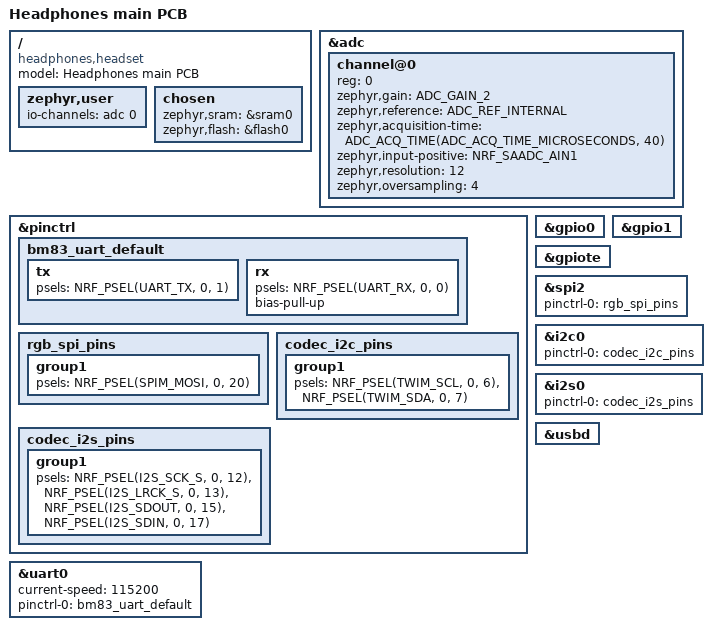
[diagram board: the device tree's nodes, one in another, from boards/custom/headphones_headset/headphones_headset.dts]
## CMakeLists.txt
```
cmake_minimum_required(VERSION 3.20.0)
list(APPEND BOARD_ROOT "${CMAKE_CURRENT_SOURCE_DIR}")
list(APPEND EXTRA_CONF_FILE "${CMAKE_CURRENT_SOURCE_DIR}/../common/radio.conf")
find_package(Zephyr REQUIRED HINTS $ENV{ZEPHYR_BASE})
project(headphone_headset)
target_sources(app PRIVATE
    src/main.c
    src/headset_logic.c
    src/battery.c
    src/bm83_link.c
    src/bm83_protocol.c
    src/codec.c
    src/rgb.c
    src/wireless_audio.c
    ../common/audio.c
    ../common/audio_fifo.c
    ../common/radio.c
    ../common/rgb_frame.c
)
target_include_directories(app PRIVATE ../common)
```

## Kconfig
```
mainmenu "Headphones"

config HEADSET_USB_VID
    hex "Assigned headset USB vendor ID"
    range 0x0000 0xffff
    default 0

config HEADSET_USB_PID
    hex "Assigned headset USB product ID"
    range 0x0000 0xffff
    default 0

source "Kconfig.zephyr"
```

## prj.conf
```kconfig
CONFIG_GPIO=y
CONFIG_ADC=y
CONFIG_PRINTK=y
CONFIG_CONSOLE=y
CONFIG_SERIAL=y
CONFIG_UART_INTERRUPT_DRIVEN=y
CONFIG_UART_CONSOLE=n
CONFIG_CLOCK_CONTROL_NRF_K32SRC_RC=y
CONFIG_USE_SEGGER_RTT=y
CONFIG_RTT_CONSOLE=y
CONFIG_SPI=y
CONFIG_I2C=y
CONFIG_USB_DEVICE_STACK_NEXT=y
CONFIG_USBD_HID_SUPPORT=y
CONFIG_BT_PERIPHERAL=y
CONFIG_BT_FILTER_ACCEPT_LIST=y
CONFIG_I2S=y
```

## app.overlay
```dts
#include "../common/flash.dtsi"

/ {
    headphone_rgb: headphone_rgb {
        compatible = "zephyr,hid-device";
        label = "Headphone RGB";
        in-report-size = <64>;
        in-polling-period-us = <4000>;
    };
};
```

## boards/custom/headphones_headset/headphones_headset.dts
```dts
/dts-v1/;

#include <nordic/nrf52840_qiaa.dtsi>
#include <zephyr/dt-bindings/adc/adc.h>
#include <zephyr/dt-bindings/adc/nrf-saadc.h>
#include <zephyr/dt-bindings/pinctrl/nrf-pinctrl.h>

/ {
    model = "Headphones main PCB";
    compatible = "headphones,headset";

    zephyr,user {
        io-channels = <&adc 0>;
    };

    chosen {
        zephyr,sram = &sram0;
        zephyr,flash = &flash0;
    };
};

&adc {
    status = "okay";
    #address-cells = <1>;
    #size-cells = <0>;

    channel@0 {
        reg = <0>;
        zephyr,gain = "ADC_GAIN_2";
        zephyr,reference = "ADC_REF_INTERNAL";
        zephyr,acquisition-time = <ADC_ACQ_TIME(ADC_ACQ_TIME_MICROSECONDS, 40)>;
        zephyr,input-positive = <NRF_SAADC_AIN1>;
        zephyr,resolution = <12>;
        zephyr,oversampling = <4>;
    };
};

&pinctrl {
    bm83_uart_default: bm83_uart_default {
        tx {
            psels = <NRF_PSEL(UART_TX, 0, 1)>;
        };
        rx {
            psels = <NRF_PSEL(UART_RX, 0, 0)>;
            bias-pull-up;
        };
    };
    rgb_spi_pins: rgb_spi_pins {
        group1 {
            psels = <NRF_PSEL(SPIM_MOSI, 0, 20)>;
        };
    };
    codec_i2c_pins: codec_i2c_pins {
        group1 {
            psels = <NRF_PSEL(TWIM_SCL, 0, 6)>,
                    <NRF_PSEL(TWIM_SDA, 0, 7)>;
        };
    };
    codec_i2s_pins: codec_i2s_pins {
        group1 {
            psels = <NRF_PSEL(I2S_SCK_S, 0, 12)>,
                    <NRF_PSEL(I2S_LRCK_S, 0, 13)>,
                    <NRF_PSEL(I2S_SDOUT, 0, 15)>,
                    <NRF_PSEL(I2S_SDIN, 0, 17)>;
        };
    };
};

&gpio0 {
    status = "okay";
};

&gpio1 {
    status = "okay";
};

&gpiote {
    status = "okay";
};

&uart0 {
    status = "okay";
    current-speed = <115200>;
    pinctrl-0 = <&bm83_uart_default>;
    pinctrl-names = "default";
};

&spi2 {
    status = "okay";
    pinctrl-0 = <&rgb_spi_pins>;
    pinctrl-names = "default";
};

&i2c0 {
    status = "okay";
    pinctrl-0 = <&codec_i2c_pins>;
    pinctrl-names = "default";
};

&i2s0 {
    status = "okay";
    pinctrl-0 = <&codec_i2s_pins>;
    pinctrl-names = "default";
};

zephyr_udc0: &usbd {
    status = "okay";
};
```

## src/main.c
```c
#include <stdbool.h>
#include <stdint.h>

#include <zephyr/device.h>
#include <zephyr/drivers/gpio.h>
#include <zephyr/kernel.h>
#include <zephyr/sys/printk.h>

#include "bm83_link.h"
#include "audio_control.h"
#include "battery.h"
#include "codec.h"
#include "headset_logic.h"
#include "rgb.h"
#include "wireless_audio.h"

enum {
    PIN_MODE_N = 29,
    PIN_PAIR_N = 4,
    PIN_PLAY_N = 24,
    PIN_DOWN_N = 0,
    PIN_UP_N = 2,
    PIN_RGB_ENABLE = 22,
    PIN_BT_AUDIO_SEL = 31,
    PIN_CHG_N = 4,
    PIN_PGOOD_N = 5,
    PIN_BOOM_N = 11,
};

static const struct device *const gpio0 = DEVICE_DT_GET(DT_NODELABEL(gpio0));
static const struct device *const gpio1 = DEVICE_DT_GET(DT_NODELABEL(gpio1));

int main(void)
{
    struct headset_inputs inputs = {0};
    struct headset_input boom = {0};
    bool bluetooth_routed = false;
    int last_charger_status = -1;

    if (!device_is_ready(gpio0) || !device_is_ready(gpio1)) {
        printk("GPIO unavailable\n");
        return 1;
    }

    if (gpio_pin_configure(gpio0, PIN_RGB_ENABLE, GPIO_OUTPUT_INACTIVE) < 0 ||
        gpio_pin_configure(gpio0, PIN_BT_AUDIO_SEL, GPIO_OUTPUT_INACTIVE) < 0 ||
        gpio_pin_configure(gpio0, PIN_CHG_N, GPIO_INPUT) < 0 ||
        gpio_pin_configure(gpio0, PIN_PGOOD_N, GPIO_INPUT) < 0 ||
        gpio_pin_configure(gpio0, PIN_MODE_N, GPIO_INPUT) < 0 ||
        gpio_pin_configure(gpio1, PIN_BOOM_N, GPIO_INPUT | GPIO_PULL_UP) < 0 ||
        gpio_pin_configure(gpio1, PIN_PAIR_N, GPIO_INPUT | GPIO_PULL_UP) < 0 ||
        gpio_pin_configure(gpio0, PIN_PLAY_N, GPIO_INPUT | GPIO_PULL_UP) < 0 ||
        gpio_pin_configure(gpio1, PIN_DOWN_N, GPIO_INPUT | GPIO_PULL_UP) < 0 ||
        gpio_pin_configure(gpio1, PIN_UP_N, GPIO_INPUT | GPIO_PULL_UP) < 0) {
        printk("GPIO setup failed\n");
        return 1;
    }

    printk("Headset bring-up\n");
    const int battery_status = battery_start();
    if (battery_status < 0) {
        printk("Battery monitor unavailable: %d\n", battery_status);
    }
    const int codec_status = codec_prepare();
    printk("Codec clock register setup: %d\n", codec_status);
    const int bt_status = bm83_start();
    if (bt_status < 0) {
        printk("BM83 UART setup failed: %d\n", bt_status);
    }
    if (codec_status == 0) {
        const int wireless_status = wireless_audio_start();
        if (wireless_status < 0) {
            printk("Dongle audio setup failed: %d\n", wireless_status);
        }
    }
    const int rgb_status = rgb_start();
    if (rgb_status < 0) {
        printk("RGB over USB unavailable: %d\n", rgb_status);
    }

    for (;;) {
        const int mode = gpio_pin_get_raw(gpio0, PIN_MODE_N);
        const int pair = gpio_pin_get_raw(gpio1, PIN_PAIR_N);
        const int play = gpio_pin_get_raw(gpio0, PIN_PLAY_N);
        const int down = gpio_pin_get_raw(gpio1, PIN_DOWN_N);
        const int up = gpio_pin_get_raw(gpio1, PIN_UP_N);
        const int pgood = gpio_pin_get_raw(gpio0, PIN_PGOOD_N);
        const int charging = gpio_pin_get_raw(gpio0, PIN_CHG_N);

        if (mode < 0 || pair < 0 || play < 0 || down < 0 || up < 0) {
            printk("Input read failed\n");
            return 1;
        }

        const uint32_t now = k_uptime_get_32();
        const bool boom_muted = !headset_boom_deployed(&boom,
            gpio_pin_get_raw(gpio1, PIN_BOOM_N) == 0, now);
        bm83_set_mic_muted(boom_muted);
        wireless_audio_set_mic_muted(boom_muted);
        if (battery_status == 0) {
            battery_poll(now);
        }
        const uint8_t events = headset_inputs_update(&inputs, mode == 0, pair == 0, now);
        const bool play_pressed = headset_button_pressed(&inputs.play, play == 0, now);
        const bool down_pressed = headset_button_pressed(&inputs.volume_down, down == 0, now);
        const bool up_pressed = headset_button_pressed(&inputs.volume_up, up == 0, now);
        if (pgood >= 0 && charging >= 0) {
            const int charger_status = pgood != 0 ? 0 : (charging == 0 ? 2 : 1);
            if (charger_status != last_charger_status) {
                const char *const statuses[] = {"No valid input", "Input valid", "Charging"};
                printk("Charger: %s\n", statuses[charger_status]);
                last_charger_status = charger_status;
            }
        }

        if ((events & HEADSET_MODE_CHANGED) != 0U) {
            printk("Requested source: %s\n", inputs.mode_bluetooth.stable ?
                   "Bluetooth" : "USB dongle");
            if (bt_status == 0) {
                bm83_set_selected(inputs.mode_bluetooth.stable);
            }
            wireless_audio_select(!inputs.mode_bluetooth.stable);
        }
        if (!inputs.mode_bluetooth.stable) {
            if ((events & HEADSET_PAIR_PRESSED) != 0U) {
                wireless_audio_pair();
            }
            if (play_pressed) {
                wireless_audio_media(AUDIO_PLAY_PAUSE);
            }
            if (down_pressed) {
                wireless_audio_media(AUDIO_VOLUME_DOWN);
            }
            if (up_pressed) {
                wireless_audio_media(AUDIO_VOLUME_UP);
            }
        }
        if (bt_status == 0) {
            if ((events & HEADSET_PAIR_PRESSED) != 0U) {
                bm83_request_pairing();
            }
            if (play_pressed) {
                bm83_request_media(BM83_MEDIA_PLAY_PAUSE);
            }
            if (down_pressed) {
                bm83_request_media(BM83_MEDIA_VOLUME_DOWN);
            }
            if (up_pressed) {
                bm83_request_media(BM83_MEDIA_VOLUME_UP);
            }
            bm83_poll();
            const bool route_bluetooth = bm83_audio_available();
            if (route_bluetooth != bluetooth_routed) {
                if (gpio_pin_set(gpio0, PIN_BT_AUDIO_SEL, route_bluetooth) < 0) {
                    printk("Audio switch update failed\n");
                    return 1;
                }
                bluetooth_routed = route_bluetooth;
            }
        }

        rgb_poll(pgood <= 0);
        wireless_audio_poll();
        k_msleep(5);
    }
}
```

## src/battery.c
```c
#include "battery.h"

#include <errno.h>
#include <stdbool.h>
#include <zephyr/drivers/adc.h>
#include <zephyr/sys/printk.h>

enum {
    SAMPLE_PERIOD_MS = 30000,
    PACK_DIVIDER_UPPER_KOHMS = 1000,
    PACK_DIVIDER_LOWER_KOHMS = 56,
};

static const struct adc_dt_spec pack_adc = ADC_DT_SPEC_GET(DT_PATH(zephyr_user));
static uint32_t last_sample;
static bool sampled;

int battery_start(void)
{
    return adc_is_ready_dt(&pack_adc) ? adc_channel_setup_dt(&pack_adc) : -ENODEV;
}

void battery_poll(uint32_t now)
{
    if (sampled && now - last_sample < SAMPLE_PERIOD_MS) {
        return;
    }
    sampled = true;
    last_sample = now;

    int16_t sample;
    struct adc_sequence sequence = {.buffer = &sample, .buffer_size = sizeof(sample)};
    int status = adc_sequence_init_dt(&pack_adc, &sequence);
    if (status == 0) {
        status = adc_read_dt(&pack_adc, &sequence);
    }
    if (status < 0) {
        printk("Battery ADC error: %d\n", status);
        return;
    }
    if (sample <= 0) {
        printk("Battery: pack voltage unavailable\n");
        return;
    }

    int32_t sense_uv = sample;
    status = adc_raw_to_microvolts_dt(&pack_adc, &sense_uv);
    if (status < 0) {
        printk("Battery conversion error: %d\n", status);
        return;
    }
    const int32_t pack_mv = sense_uv * (PACK_DIVIDER_UPPER_KOHMS + PACK_DIVIDER_LOWER_KOHMS) /
                            (1000 * PACK_DIVIDER_LOWER_KOHMS);
    printk("Battery: %d mV\n", (int)pack_mv);
}
```

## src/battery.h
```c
#ifndef HEADPHONES_BATTERY_H
#define HEADPHONES_BATTERY_H

#include <stdint.h>

int battery_start(void);
void battery_poll(uint32_t now);

#endif
```

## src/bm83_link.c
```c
#include "bm83_link.h"
#include "bm83_protocol.h"

#include <errno.h>
#include <stdint.h>
#include <zephyr/device.h>
#include <zephyr/drivers/gpio.h>
#include <zephyr/drivers/uart.h>
#include <zephyr/kernel.h>
#include <zephyr/sys/atomic.h>
#include <zephyr/sys/printk.h>
#include <zephyr/sys/ring_buffer.h>

enum {
    PIN_MFB = 6,
    ACK_MS = 200,
    RESPONSE_MS = 800,
    POWER_ON_MS = 2000,
    PAIR_MS = 30000,
    RX_GAP_MS = 30,
    MAX_ATTEMPTS = 3,
};

static const struct device *const serial = DEVICE_DT_GET(DT_NODELABEL(uart0));
static const struct device *const mfb_gpio = DEVICE_DT_GET(DT_NODELABEL(gpio1));
RING_BUF_DECLARE(received, 1024);
K_MSGQ_DEFINE(media_queue, sizeof(enum bm83_media_control), 8, 1);
static atomic_t rx_overflow;
static struct bm83_parser parser;
static uint32_t last_rx;
static uint32_t sent_at;
static uint32_t pair_started;
static uint32_t power_started;
static uint8_t awaiting;
static uint8_t action;
static uint8_t command_link;
static uint8_t attempts;
static uint8_t handsfree_links;
static uint8_t hf_device[2];
static uint8_t media_links;
static uint8_t call_link = UINT8_MAX;
static bool command_pending;
static bool command_acknowledged;
static bool selected;
static bool probe_needed;
static bool responsive;
static bool pair_requested;
static bool pairing;
static bool exit_pairing;
static bool power_release_needed;
static bool power_requested;
static bool power_starting;
static bool powered;
static bool mic_muted = true;
static bool mic_update_pending;

static void command_failed(void)
{
    command_pending = false;
    if (awaiting == BM83_CMD_VERSION ||
        (awaiting == BM83_CMD_MMI &&
         (action == BM83_ACTION_POWER_PRESS || action == BM83_ACTION_POWER_RELEASE))) {
        pair_requested = false;
        power_requested = false;
    }
}

static void receive_irq(const struct device *dev, void *context)
{
    uint8_t bytes[32];
    (void)context;

    if (!uart_irq_update(dev) || !uart_irq_rx_ready(dev)) {
        return;
    }
    int count;
    while ((count = uart_fifo_read(dev, bytes, sizeof(bytes))) > 0) {
        if (ring_buf_put(&received, bytes, (uint32_t)count) != (uint32_t)count) {
            atomic_set(&rx_overflow, 1);
        }
    }
}

static int send_frame(uint8_t command, const uint8_t *params, size_t count)
{
    uint8_t frame[12];
    const size_t length = bm83_encode(frame, sizeof(frame), command, params, count);
    if (length == 0U) {
        return -EINVAL;
    }
    int status = gpio_pin_set(mfb_gpio, PIN_MFB, 1);
    if (status < 0) {
        return status;
    }
    k_busy_wait(2500);
    for (size_t i = 0; i < length; ++i) {
        uart_poll_out(serial, frame[i]);
    }
    k_busy_wait(100);
    return gpio_pin_set(mfb_gpio, PIN_MFB, 0);
}

static void send_pending(void)
{
    uint8_t params[6] = {command_link, action};
    size_t count = awaiting == BM83_CMD_VERSION ? 1U : 2U;
    if (awaiting == BM83_CMD_SET_GAIN) {
        params[0] = call_link < 2U ? call_link : (media_links & 1U ? 0U : 1U);
        params[1] = call_link < 2U ? 0x02 : 0x01;
        params[2] = action;
        count = sizeof(params);
    }
    const int status = send_frame(awaiting, params, count);
    sent_at = k_uptime_get_32();
    ++attempts;
    command_pending = status == 0;
    command_acknowledged = false;
    if (status < 0) {
        command_failed();
        printk("BM83 transmit GPIO error: %d\n", status);
    }
}

static void queue_command(uint8_t command, uint8_t mmi_action, uint8_t link)
{
    awaiting = command;
    action = mmi_action;
    command_link = link;
    attempts = 0;
    send_pending();
}

static void handle_event(uint32_t now)
{
    const uint8_t event = parser.body[0];

    if (event == BM83_EVENT_COMMAND_ACK) {
        if (parser.length < 3U || !command_pending || parser.body[1] != awaiting) {
            return;
        }
        if (parser.body[2] != 0U) {
            printk("BM83 rejected 0x%02x: 0x%02x\n", awaiting, parser.body[2]);
            command_failed();
        } else if (awaiting == BM83_CMD_MMI) {
            command_pending = false;
            switch (action) {
            case BM83_ACTION_POWER_PRESS:
                power_release_needed = true;
                break;
            case BM83_ACTION_POWER_RELEASE:
                power_starting = !powered;
                power_started = now;
                printk("BM83 accepted power-on sequence\n");
                break;
            case BM83_ACTION_MIC_MUTE:
            case BM83_ACTION_MIC_UNMUTE:
                break;
            default:
                pairing = action == BM83_ACTION_PAIR;
                pair_started = now;
                exit_pairing = pairing && !selected;
                printk("BM83 accepted pairing %s\n", pairing ? "start" : "exit");
                break;
            }
        } else if (awaiting == BM83_CMD_VERSION) {
            command_acknowledged = true;
            sent_at = now;
        } else {
            command_pending = false;
        }
        return;
    }

    if (send_frame(BM83_CMD_EVENT_ACK, &event, 1) < 0) {
        printk("BM83 event acknowledgement failed\n");
    }
    if (event == BM83_EVENT_VERSION && parser.length >= 4U && parser.body[1] == 0U) {
        responsive = true;
        if (command_pending && awaiting == BM83_CMD_VERSION) {
            command_pending = false;
        }
        printk("BM83 UART version reply received\n");
    } else if (event == BM83_EVENT_STATUS && parser.length >= 2U) {
        const uint8_t link = parser.length >= 3U ? parser.body[2] & 0x0fU : UINT8_MAX;
        const uint8_t mask = link < 2U ? 1U << link : 0U;
        printk("BM83 status 0x%02x\n", parser.body[1]);
        switch (parser.body[1]) {
        case 0x00:
            powered = false;
            pairing = false;
            handsfree_links = 0U;
            media_links = 0U;
            call_link = UINT8_MAX;
            break;
        case 0x01:
            powered = true;
            if (!pairing) {
                pair_started = now;
            }
            pairing = true;
            exit_pairing |= !selected;
            break;
        case 0x02:
            powered = true;
            break;
        case 0x03:
        case 0x04:
            pairing = false;
            exit_pairing = false;
            break;
        case 0x05:
            handsfree_links |= mask;
            if (mask != 0U) {
                hf_device[link] = parser.body[2] >> 4;
            }
            powered = true;
            break;
        case 0x06:
            media_links |= mask;
            powered = true;
            break;
        case 0x07:
            handsfree_links &= ~mask;
            if (call_link == link) {
                call_link = UINT8_MAX;
            }
            break;
        case 0x08:
            media_links &= ~mask;
            break;
        case 0x09:
            call_link = UINT8_MAX;
            for (uint8_t index = 0; index < 2U; ++index) {
                if ((handsfree_links & (1U << index)) != 0U && hf_device[index] == link) {
                    call_link = index;
                    mic_update_pending = true;
                    break;
                }
            }
            break;
        case 0x0a:
            call_link = UINT8_MAX;
            break;
        default:
            break;
        }
    }
}

int bm83_start(void)
{
    if (!device_is_ready(serial) || !device_is_ready(mfb_gpio)) {
        return -ENODEV;
    }
    int status = gpio_pin_configure(mfb_gpio, PIN_MFB, GPIO_OUTPUT_INACTIVE);
    if (status < 0) {
        return status;
    }
    status = uart_irq_callback_user_data_set(serial, receive_irq, NULL);
    if (status < 0) {
        return status;
    }
    uart_irq_rx_enable(serial);
    return 0;
}

void bm83_set_selected(bool enabled)
{
    mic_update_pending |= selected != enabled;
    selected = enabled;
    if (enabled && !responsive && !command_pending) {
        probe_needed = true;
    }
    power_requested = enabled && !powered;
    if (!enabled) {
        pair_requested = false;
        exit_pairing |= pairing;
        k_msgq_purge(&media_queue);
    }
}

void bm83_set_mic_muted(bool muted)
{
    mic_update_pending |= mic_muted != muted;
    mic_muted = muted;
}

void bm83_request_media(enum bm83_media_control control)
{
    if (selected && powered) {
        (void)k_msgq_put(&media_queue, &control, K_NO_WAIT);
    }
}

void bm83_request_pairing(void)
{
    if (selected) {
        pair_requested = true;
        power_requested |= !powered;
        probe_needed |= !responsive && !command_pending;
    }
}

bool bm83_audio_available(void)
{
    return selected && powered;
}

void bm83_poll(void)
{
    uint32_t now = k_uptime_get_32();
    uint8_t byte;

    if (atomic_cas(&rx_overflow, 1, 0) || now - last_rx > RX_GAP_MS) {
        parser.count = 0;
    }
    while (ring_buf_get(&received, &byte, 1) == 1U) {
        last_rx = now;
        if (bm83_parse_byte(&parser, byte)) {
            handle_event(now);
        }
    }

    now = k_uptime_get_32();
    if (power_starting && (powered || now - power_started >= POWER_ON_MS)) {
        power_starting = false;
        if (!powered) {
            pair_requested = false;
            printk("BM83 did not report power on\n");
        }
    }
    if (command_pending) {
        const uint32_t wait = command_acknowledged ? RESPONSE_MS : ACK_MS;
        if (now - sent_at < wait) {
            return;
        }
        const bool stale_mic_command = awaiting == BM83_CMD_MMI &&
            (action == BM83_ACTION_MIC_MUTE || action == BM83_ACTION_MIC_UNMUTE) &&
            (command_link != call_link ||
             action != ((mic_muted || !selected) ? BM83_ACTION_MIC_MUTE : BM83_ACTION_MIC_UNMUTE));
        if (!stale_mic_command && attempts < MAX_ATTEMPTS &&
            (awaiting == BM83_CMD_VERSION || awaiting == BM83_CMD_MMI)) {
            send_pending();
            return;
        }
        printk("BM83 command 0x%02x timed out\n", awaiting);
        command_failed();
    }
    if (power_release_needed) {
        power_release_needed = false;
        queue_command(BM83_CMD_MMI, BM83_ACTION_POWER_RELEASE, 0);
    } else if (mic_update_pending && powered && call_link < 2U) {
        mic_update_pending = false;
        queue_command(BM83_CMD_MMI,
            (mic_muted || !selected) ? BM83_ACTION_MIC_MUTE : BM83_ACTION_MIC_UNMUTE, call_link);
    } else if (probe_needed && selected) {
        probe_needed = false;
        queue_command(BM83_CMD_VERSION, 0, 0);
    } else if (exit_pairing || (pairing && now - pair_started >= PAIR_MS)) {
        exit_pairing = false;
        pairing = false;
        queue_command(BM83_CMD_MMI, BM83_ACTION_EXIT_PAIR, 0);
    } else if (selected && responsive && power_requested && !power_starting) {
        power_requested = false;
        if (!powered) {
            queue_command(BM83_CMD_MMI, BM83_ACTION_POWER_PRESS, 0);
        }
    } else if (selected && responsive && powered && pair_requested) {
        pair_requested = false;
        queue_command(BM83_CMD_MMI, BM83_ACTION_PAIR, 0);
    } else if (selected && powered) {
        enum bm83_media_control control;
        if (k_msgq_get(&media_queue, &control, K_NO_WAIT) != 0) {
            return;
        }
        if (control == BM83_MEDIA_PLAY_PAUSE && media_links != 0U && call_link == UINT8_MAX) {
            queue_command(BM83_CMD_MUSIC_CONTROL, 0x07, 0);
        } else if (control != BM83_MEDIA_PLAY_PAUSE &&
                   (media_links != 0U || call_link < 2U)) {
            queue_command(BM83_CMD_SET_GAIN, control == BM83_MEDIA_VOLUME_UP ? 0x01 : 0x02, 0);
        }
    }
}
```

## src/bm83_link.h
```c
#ifndef BM83_LINK_H
#define BM83_LINK_H

#include <stdbool.h>

enum bm83_media_control {
    BM83_MEDIA_PLAY_PAUSE,
    BM83_MEDIA_VOLUME_DOWN,
    BM83_MEDIA_VOLUME_UP,
};

int bm83_start(void);
void bm83_poll(void);
void bm83_set_selected(bool selected);
void bm83_set_mic_muted(bool muted);
void bm83_request_pairing(void);
void bm83_request_media(enum bm83_media_control control);
bool bm83_audio_available(void);

#endif
```

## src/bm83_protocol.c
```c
#include "bm83_protocol.h"

#include <string.h>

bool bm83_parse_byte(struct bm83_parser *parser, uint8_t byte)
{
    switch (parser->count) {
    case 0:
        if (byte == BM83_START) {
            parser->count = 1;
        }
        return false;
    case 1:
        parser->length = (uint16_t)byte << 8;
        parser->checksum = byte;
        break;
    case 2:
        parser->length |= byte;
        if (parser->length == 0U || parser->length > sizeof(parser->body)) {
            parser->count = byte == BM83_START ? 1U : 0U;
            return false;
        }
        break;
    default:
        if (parser->count == parser->length + 3U) {
            const bool valid = (uint8_t)(parser->checksum + byte) == 0U;
            parser->count = !valid && byte == BM83_START ? 1U : 0U;
            return valid;
        }
        parser->body[parser->count - 3U] = byte;
        break;
    }
    if (parser->count > 1U) {
        parser->checksum = (uint8_t)(parser->checksum + byte);
    }
    ++parser->count;
    return false;
}

size_t bm83_encode(uint8_t *out, size_t capacity, uint8_t command,
                   const uint8_t *params, size_t count)
{
    if (count >= BM83_MAX_BODY || capacity < count + 5U ||
        (count != 0U && params == NULL)) {
        return 0;
    }

    const uint16_t length = (uint16_t)(count + 1U);
    out[0] = BM83_START;
    out[1] = (uint8_t)(length >> 8);
    out[2] = (uint8_t)length;
    out[3] = command;
    if (count != 0U) {
        memcpy(&out[4], params, count);
    }

    uint8_t checksum = 0;
    for (size_t i = 1; i < count + 4U; ++i) {
        checksum = (uint8_t)(checksum + out[i]);
    }
    out[4U + count] = (uint8_t)(0U - checksum);
    return count + 5U;
}
```

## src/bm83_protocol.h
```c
#ifndef BM83_PROTOCOL_H
#define BM83_PROTOCOL_H

#include <stdbool.h>
#include <stddef.h>
#include <stdint.h>

enum {
    BM83_START = 0xaa,
    BM83_MAX_BODY = 512,
    BM83_EVENT_COMMAND_ACK = 0x00,
    BM83_EVENT_STATUS = 0x01,
    BM83_EVENT_VERSION = 0x18,
    BM83_CMD_MMI = 0x02,
    BM83_CMD_MUSIC_CONTROL = 0x04,
    BM83_CMD_VERSION = 0x08,
    BM83_CMD_EVENT_ACK = 0x14,
    BM83_CMD_SET_GAIN = 0x23,
    BM83_ACTION_MIC_MUTE = 0x08,
    BM83_ACTION_MIC_UNMUTE = 0x09,
    BM83_ACTION_POWER_PRESS = 0x51,
    BM83_ACTION_POWER_RELEASE = 0x52,
    BM83_ACTION_PAIR = 0x5d,
    BM83_ACTION_EXIT_PAIR = 0x6b,
};

struct bm83_parser {
    uint16_t count;
    uint16_t length;
    uint8_t checksum;
    uint8_t body[BM83_MAX_BODY];
};

bool bm83_parse_byte(struct bm83_parser *parser, uint8_t byte);
size_t bm83_encode(uint8_t *out, size_t capacity, uint8_t command,
                   const uint8_t *params, size_t count);

#endif
```

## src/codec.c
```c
#include "codec.h"

#include <errno.h>
#include <zephyr/drivers/gpio.h>
#include <zephyr/drivers/i2c.h>
#include <zephyr/kernel.h>

enum {
    AIC3204_ADDRESS = 0x18,
    CODEC_RESET_PIN = 8,
    PAGE_SELECT = 0,
    SOFTWARE_RESET = 1,
    CLOCK_SOURCE = 4,
    NDAC = 11,
    MDAC = 12,
    DOSR_HIGH = 13,
    DOSR_LOW = 14,
    NADC = 18,
    MADC = 19,
    AOSR = 20,
    AUDIO_INTERFACE = 27,
    BCLK_SOURCE = 29,
    BCLK_DIV = 30,
    POWERED_DIVIDER = 0x80,
};

static const struct device *const i2c = DEVICE_DT_GET(DT_NODELABEL(i2c0));
static const struct device *const gpio = DEVICE_DT_GET(DT_NODELABEL(gpio0));

static const uint8_t digital_registers[][2] = {
    {CLOCK_SOURCE, 0},
    {NDAC, POWERED_DIVIDER | 1},
    {MDAC, POWERED_DIVIDER | 2},
    {DOSR_HIGH, 0},
    {DOSR_LOW, 128},
    {NADC, POWERED_DIVIDER | 1},
    {MADC, POWERED_DIVIDER | 2},
    {AOSR, 128},
    {BCLK_SOURCE, 0x05},
    {BCLK_DIV, POWERED_DIVIDER | 4},
    {AUDIO_INTERFACE, 0x0c},
};

static int write_register(uint8_t reg, uint8_t value)
{
    return i2c_reg_write_byte(i2c, AIC3204_ADDRESS, reg, value);
}

static const uint8_t audio_start[][2] = {
    {PAGE_SELECT, 1},
    {1, 0x08},
    {2, 0x00},
    {123, 0x01},
    {20, 0x25},
    {10, 0x00},
    {12, 0x08},
    {13, 0x08},
    {16, 0x00},
    {17, 0x00},
    {51, 0x68},
    {52, 0x40},
    {54, 0x40},
    {59, 0x18},
    {9, 0x30},
    {PAGE_SELECT, 0},
    {60, 0x01},
    {61, 0x01},
    {63, 0xd6},
    {64, 0x0c},
    {65, 0xd0},
    {66, 0xd0},
    {81, 0x80},
    {82, 0x08},
};

static int write_table(const uint8_t (*settings)[2], size_t count)
{
    for (size_t i = 0; i < count; ++i) {
        const int status = write_register(settings[i][0], settings[i][1]);
        if (status != 0) {
            return status;
        }
    }
    return 0;
}

int codec_audio_start(void)
{
    return write_table(audio_start, ARRAY_SIZE(audio_start));
}

int codec_audio_unmute(void)
{
    uint8_t headphone_status;
    int status = write_register(PAGE_SELECT, 1);
    if (status == 0) {
        status = i2c_reg_read_byte(i2c, AIC3204_ADDRESS, 63, &headphone_status);
    }
    if (status != 0) {
        return status;
    }
    status = write_register(PAGE_SELECT, 0);
    if (status != 0) {
        return status;
    }
    return (headphone_status & 0xc0U) == 0xc0U ? write_register(64, 0) : -EAGAIN;
}

int codec_audio_stop(void)
{
    const uint8_t stop[][2] = {
        {PAGE_SELECT, 0}, {64, 0x0c}, {82, 0x88}, {81, 0}, {63, 0},
        {PAGE_SELECT, 1}, {9, 0}, {51, 0}, {2, 0x08}, {PAGE_SELECT, 0},
    };
    const int status = write_table(stop, ARRAY_SIZE(stop));
    if (status != 0) {
        (void)gpio_pin_set_raw(gpio, CODEC_RESET_PIN, 0);
    }
    return status;
}

static int configure_clocks(void)
{
    int status = write_register(PAGE_SELECT, 0);
    if (status != 0) {
        return status;
    }
    status = write_register(SOFTWARE_RESET, 1);
    if (status != 0) {
        return status;
    }
    k_msleep(2);
    for (size_t i = 0; i < ARRAY_SIZE(digital_registers); ++i) {
        const uint8_t reg = digital_registers[i][0];
        const uint8_t expected = digital_registers[i][1];
        status = write_register(reg, expected);
        if (status != 0) {
            return status;
        }
        uint8_t value;
        status = i2c_reg_read_byte(i2c, AIC3204_ADDRESS, reg, &value);
        if (status != 0) {
            return status;
        }
        if (value != expected) {
            return -EIO;
        }
    }
    return 0;
}

int codec_prepare(void)
{
    if (!device_is_ready(i2c) || !device_is_ready(gpio)) {
        return -ENODEV;
    }
    int status = gpio_pin_configure(gpio, CODEC_RESET_PIN, GPIO_OUTPUT_LOW | GPIO_OPEN_DRAIN);
    if (status != 0) {
        return status;
    }
    k_msleep(2);
    status = gpio_pin_set_raw(gpio, CODEC_RESET_PIN, 1);
    if (status != 0) {
        return status;
    }
    k_msleep(10);
    status = configure_clocks();
    if (status != 0) {
        (void)gpio_pin_set_raw(gpio, CODEC_RESET_PIN, 0);
    }
    return status;
}
```

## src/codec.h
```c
#ifndef HEADSET_CODEC_H
#define HEADSET_CODEC_H

int codec_prepare(void);
int codec_audio_start(void);
int codec_audio_unmute(void);
int codec_audio_stop(void);

#endif
```

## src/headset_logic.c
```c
#include "headset_logic.h"

enum { DEBOUNCE_MS = 25 };

static bool input_changed(struct headset_input *input, bool sample, uint32_t now_ms)
{
    if (!input->initialized) {
        input->candidate = sample;
        input->stable = sample;
        input->changed_ms = now_ms;
        input->initialized = true;
        return true;
    }

    if (input->candidate != sample) {
        input->candidate = sample;
        input->changed_ms = now_ms;
    }

    if (input->stable != sample && now_ms - input->changed_ms >= DEBOUNCE_MS) {
        input->stable = sample;
        return true;
    }
    return false;
}

bool headset_button_pressed(struct headset_input *input, bool down, uint32_t now_ms)
{
    const bool initialized = input->initialized;
    return input_changed(input, down, now_ms) && initialized && input->stable;
}

bool headset_boom_deployed(struct headset_input *input, bool closed, uint32_t now_ms)
{
    if (!input->initialized || !closed) {
        input->initialized = true;
        input->candidate = false;
        input->stable = false;
    }
    (void)input_changed(input, closed, now_ms);
    return input->stable;
}

uint8_t headset_inputs_update(struct headset_inputs *inputs, bool bluetooth,
                              bool pair_down, uint32_t now_ms)
{
    uint8_t events = 0;

    if (input_changed(&inputs->mode_bluetooth, bluetooth, now_ms)) {
        events |= HEADSET_MODE_CHANGED;
    }
    if (headset_button_pressed(&inputs->pair, pair_down, now_ms)) {
        events |= HEADSET_PAIR_PRESSED;
    }
    return events;
}
```

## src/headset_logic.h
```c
#ifndef HEADSET_LOGIC_H
#define HEADSET_LOGIC_H

#include <stdbool.h>
#include <stdint.h>

enum headset_event {
    HEADSET_MODE_CHANGED = 1U << 0,
    HEADSET_PAIR_PRESSED = 1U << 1,
};

struct headset_input {
    uint32_t changed_ms;
    bool initialized;
    bool candidate;
    bool stable;
};

struct headset_inputs {
    struct headset_input mode_bluetooth;
    struct headset_input pair;
    struct headset_input play;
    struct headset_input volume_down;
    struct headset_input volume_up;
};

bool headset_button_pressed(struct headset_input *input, bool down, uint32_t now_ms);
bool headset_boom_deployed(struct headset_input *input, bool closed, uint32_t now_ms);
uint8_t headset_inputs_update(struct headset_inputs *inputs, bool bluetooth,
                              bool pair_down, uint32_t now_ms);

#endif
```

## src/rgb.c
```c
#include "rgb.h"
#include "rgb_frame.h"

#include <errno.h>
#include <string.h>
#include <zephyr/device.h>
#include <zephyr/drivers/gpio.h>
#include <zephyr/drivers/spi.h>
#include <zephyr/kernel.h>
#include <zephyr/sys/atomic.h>
#include <zephyr/sys/printk.h>
#include <zephyr/usb/class/usbd_hid.h>
#include <zephyr/usb/usbd.h>

enum {
    RGB_ENABLE_PIN = 22,
    CHARGER_EN1_PIN = 26,
    CHARGER_EN2_PIN = 13,
    SYMBOL_BITS = 10,
    RESET_BYTES = 320,
    CHANNEL_SUM_LIMIT = 4800,
    EXTERNAL_POWER_CHANNEL_SUM_LIMIT = 960,
};

static const struct device *const gpio = DEVICE_DT_GET(DT_NODELABEL(gpio0));
static const struct device *const gpio1 = DEVICE_DT_GET(DT_NODELABEL(gpio1));
static const struct device *const spi = DEVICE_DT_GET(DT_NODELABEL(spi2));
static const struct device *const hid = DEVICE_DT_GET(DT_NODELABEL(headphone_rgb));
static const struct spi_config spi_config = {
    .frequency = 8000000,
    .operation = SPI_OP_MODE_MASTER | SPI_WORD_SET(8),
};
struct pixels {
    uint8_t data[RGB_FRAME_BYTES];
    uint32_t received_at;
    bool valid;
    bool pending;
};

static uint8_t wave[RGB_FRAME_BYTES * SYMBOL_BITS + RESET_BYTES];
static struct rgb_frame staged;
static struct pixels usb_pixels;
static struct pixels wireless_pixels;
static struct k_spinlock frame_lock;
static bool rail_enabled;
static uint32_t last_channel_limit;
static atomic_t usb_lighting_allowed;
static bool usb_host_seen;
static bool usb_configured;
static bool usb_suspended;

USBD_DEVICE_DEFINE(headset_usb, DEVICE_DT_GET(DT_NODELABEL(zephyr_udc0)),
                   CONFIG_HEADSET_USB_VID, CONFIG_HEADSET_USB_PID);
USBD_DESC_LANG_DEFINE(lang);
USBD_DESC_PRODUCT_DEFINE(product, "Headphones RGB");
USBD_CONFIGURATION_DEFINE(usb_config, USB_SCD_SELF_POWERED, 250, NULL);

static const uint8_t report_descriptor[] = {RGB_HID_DESCRIPTOR_BYTES};

static int receive_report(const struct device *dev, uint8_t type, uint8_t id,
                          uint16_t len, const uint8_t *data)
{
    (void)dev;
    if (type != HID_REPORT_TYPE_FEATURE || id != RGB_REPORT_ID) {
        return -EINVAL;
    }

    const uint32_t now = k_uptime_get_32();
    k_spinlock_key_t key = k_spin_lock(&frame_lock);
    const int status = rgb_frame_accept(&staged, usb_pixels.data, data, len, now);
    if (status > 0) {
        usb_pixels.received_at = now;
        usb_pixels.valid = true;
        usb_pixels.pending = true;
    }
    k_spin_unlock(&frame_lock, key);
    return status < 0 ? status : 0;
}

static void usb_ready(const struct device *dev, bool ready)
{
    (void)dev;
    if (!ready) {
        k_spinlock_key_t key = k_spin_lock(&frame_lock);
        staged.have_left = false;
        usb_pixels.valid = false;
        k_spin_unlock(&frame_lock, key);
    }
}

void rgb_receive_wireless(const uint8_t *pixels)
{
    const uint32_t now = k_uptime_get_32();
    k_spinlock_key_t key = k_spin_lock(&frame_lock);
    memcpy(wireless_pixels.data, pixels, RGB_FRAME_BYTES);
    wireless_pixels.received_at = now;
    wireless_pixels.valid = true;
    wireless_pixels.pending = true;
    k_spin_unlock(&frame_lock, key);
}

void rgb_clear_wireless(void)
{
    k_spinlock_key_t key = k_spin_lock(&frame_lock);
    wireless_pixels.valid = false;
    k_spin_unlock(&frame_lock, key);
}

static const struct hid_device_ops hid_ops = {
    .iface_ready = usb_ready,
    .set_report = receive_report,
};

static int charger_update(void)
{
    const bool standby = usb_host_seen && usb_suspended;
    const bool enable_ilim = usb_configured || standby;
    int status;

    if (enable_ilim) {
        status = gpio_pin_set_raw(gpio1, CHARGER_EN2_PIN, 1);
        if (status == 0) {
            status = gpio_pin_set_raw(gpio, CHARGER_EN1_PIN, standby);
        }
    } else {
        status = gpio_pin_set_raw(gpio, CHARGER_EN1_PIN, 0);
        if (status == 0) {
            status = gpio_pin_set_raw(gpio1, CHARGER_EN2_PIN, 0);
        }
    }
    return status;
}

static void usb_message(struct usbd_context *ctx, const struct usbd_msg *msg)
{
    int status = 0;
    switch (msg->type) {
    case USBD_MSG_VBUS_READY:
        status = usbd_enable(ctx);
        break;
    case USBD_MSG_VBUS_REMOVED:
        usb_ready(hid, false);
        status = usbd_disable(ctx);
        usb_host_seen = false;
        usb_configured = false;
        usb_suspended = false;
        break;
    case USBD_MSG_RESET:
        usb_host_seen = true;
        usb_configured = false;
        usb_suspended = false;
        break;
    case USBD_MSG_CONFIGURATION:
        usb_host_seen = true;
        usb_configured = msg->status != 0;
        break;
    case USBD_MSG_SUSPEND:
        usb_suspended = true;
        break;
    case USBD_MSG_RESUME:
        usb_suspended = false;
        break;
    default:
        return;
    }
    if (status < 0) {
        printk("RGB USB VBUS event failed: %d\n", status);
    }
    status = charger_update();
    atomic_set(&usb_lighting_allowed, status == 0 && usb_configured && !usb_suspended);
    if (status < 0) {
        printk("Charger mode update failed: %d\n", status);
    }
}

int rgb_start(void)
{
    if (CONFIG_HEADSET_USB_VID == 0 || CONFIG_HEADSET_USB_PID == 0) {
        return -ENOTSUP;
    }
    if (!device_is_ready(hid) || !device_is_ready(spi)) {
        return -ENODEV;
    }
    int status = gpio_pin_configure(gpio, CHARGER_EN1_PIN, GPIO_OUTPUT_INACTIVE);
    if (status == 0) {
        status = gpio_pin_configure(gpio1, CHARGER_EN2_PIN, GPIO_OUTPUT_INACTIVE);
    }
    if (status == 0) {
        status = hid_device_register(hid, report_descriptor, sizeof(report_descriptor), &hid_ops);
    }
    if (status == 0) {
        status = usbd_add_descriptor(&headset_usb, &lang);
    }
    if (status == 0) {
        status = usbd_add_descriptor(&headset_usb, &product);
    }
    if (status == 0) {
        status = usbd_add_configuration(&headset_usb, USBD_SPEED_FS, &usb_config);
    }
    if (status == 0) {
        status = usbd_register_class(&headset_usb, "hid_0", USBD_SPEED_FS, 1);
    }
    if (status == 0) {
        status = usbd_msg_register_cb(&headset_usb, usb_message);
    }
    if (status == 0) {
        usbd_self_powered(&headset_usb, true);
        status = usbd_init(&headset_usb);
    }
    if (status == 0 && !usbd_can_detect_vbus(&headset_usb)) {
        status = usbd_enable(&headset_usb);
    }
    return status;
}

static void encode_channel(uint8_t *out, uint8_t value)
{
    uint32_t bits = 0;
    unsigned int held = 0;
    for (uint8_t bit = 0x80; bit != 0; bit >>= 1) {
        bits = (bits << SYMBOL_BITS) | ((value & bit) != 0 ? 0x3e0U : 0x380U);
        held += SYMBOL_BITS;
        while (held >= 8U) {
            held -= 8U;
            *out++ = (uint8_t)(bits >> held);
        }
    }
}

static int send_pixels(const uint8_t *rgb, uint32_t sum, uint32_t limit)
{
    const uint8_t channel_order[] = {1, 0, 2};
    uint8_t *out = wave;
    for (size_t pixel = 0; pixel < RGB_FRAME_BYTES; pixel += RGB_CHANNELS) {
        for (size_t channel = 0; channel < RGB_CHANNELS; ++channel) {
            uint8_t value = rgb[pixel + channel_order[channel]];
            if (sum > limit) {
                value = (uint32_t)value * limit / sum;
            }
            encode_channel(out, value);
            out += SYMBOL_BITS;
        }
    }
    const struct spi_buf buffer = {.buf = wave, .len = sizeof(wave)};
    const struct spi_buf_set tx = {.buffers = &buffer, .count = 1};
    return spi_write(spi, &spi_config, &tx);
}

static void turn_off(void)
{
    if (rail_enabled && gpio_pin_set(gpio, RGB_ENABLE_PIN, 0) == 0) {
        rail_enabled = false;
    }
}

void rgb_poll(bool external_power)
{
    if (!device_is_ready(spi)) {
        return;
    }
    const uint32_t limit = !external_power ? CHANNEL_SUM_LIMIT :
        (atomic_get(&usb_lighting_allowed) ? EXTERNAL_POWER_CHANNEL_SUM_LIMIT : 0U);
    if (limit == 0U) {
        turn_off();
        last_channel_limit = 0U;
        return;
    }
    uint8_t pixels[RGB_FRAME_BYTES];
    k_spinlock_key_t key = k_spin_lock(&frame_lock);
    const uint32_t now = k_uptime_get_32();
    usb_pixels.valid &= now - usb_pixels.received_at < RGB_TIMEOUT_MS;
    wireless_pixels.valid &= now - wireless_pixels.received_at < RGB_TIMEOUT_MS;
    struct pixels *const source = usb_pixels.valid ? &usb_pixels : &wireless_pixels;
    const bool active = source->valid;
    const bool ready = active && (source->pending || limit != last_channel_limit);
    if (ready) {
        memcpy(pixels, source->data, sizeof(pixels));
        source->pending = false;
        (source == &usb_pixels ? &wireless_pixels : &usb_pixels)->pending = true;
    }
    k_spin_unlock(&frame_lock, key);
    if (!active) {
        turn_off();
        return;
    }
    if (!ready) {
        return;
    }

    uint32_t sum = 0;
    for (size_t i = 0; i < sizeof(pixels); ++i) {
        sum += pixels[i];
    }
    if (sum == 0U) {
        turn_off();
        return;
    }
    if (!rail_enabled) {
        if (gpio_pin_set(gpio, RGB_ENABLE_PIN, 1) < 0) {
            return;
        }
        rail_enabled = true;
        k_msleep(10);
    }
    if (send_pixels(pixels, sum, limit) < 0) {
        turn_off();
        printk("RGB SPI transfer failed\n");
        return;
    }
    last_channel_limit = limit;
}
```

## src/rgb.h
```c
#ifndef HEADSET_RGB_H
#define HEADSET_RGB_H

#include <stdbool.h>
#include <stdint.h>

int rgb_start(void);
void rgb_poll(bool external_power);
void rgb_receive_wireless(const uint8_t *pixels);
void rgb_clear_wireless(void);

#endif
```
